# LPC8N04 register map
File version: 0.1
CPU: CM0PLUS r0p0, little endian, no MPU, no FPU, 2 interrupt priority bits
Registers are 32-bit, read-write, no defined reset value unless marked. A register's access mark holds for its fields unless they carry their own. Offsets are from the block's base; [hi:lo] are bit positions; {n}, {i} and the like mark numbered series; 'fields as' and 'values as' point back to an identical list.

## I2C0 — I2C Bus Controller 0
Base 0x40000000
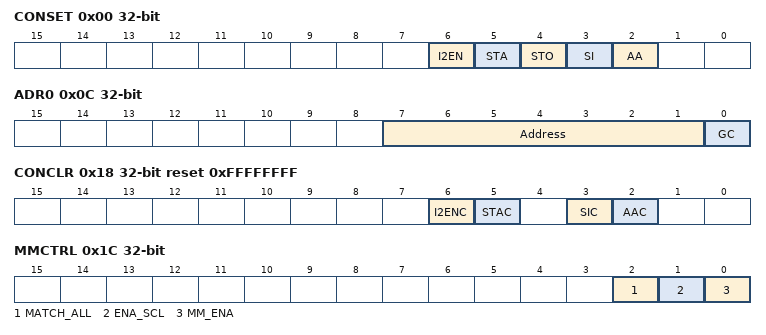
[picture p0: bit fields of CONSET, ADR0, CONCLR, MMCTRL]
0x00 CONSET — I2C Control Set Register. When a one is written to a bit of this register, the corresponding bit in the I2C control register is set. Writing a zero has no effect on the corresponding bit in the I2C control register.
  [6] I2EN — I2C interface enable
  [5] STA — START flag
  [4] STO — STOP flag
  [3] SI — I2C interrupt flag
  [2] AA — Assert acknowledge flag
0x04 STAT ro reset 0xF8 (reset mask 0x0) — I2C Status Register. During I2C operation, this register provides detailed status codes that allow software to determine the next action needed.
  [7:3] Status — Actual status information about the I2C interface
0x08 DAT — I2C Data Register. During master or slave transmit mode, data to be transmitted is written to this register. During master or slave receive mode, data that has been received may be read from this register.
  [7:0] Data — This register holds data values that have been received or are to be transmitted.
0x0C ADR0 — I2C Slave Address Register 0. Contains the 7-bit slave address for operation of the I2C interface in slave mode, and is not used in master mode. The least significant bit determines whether a slave responds to the General Call address. This address is also used for device wakeup.
  [7:1] Address — The I2C device address in slave ode
  [0] GC — General call enable bit
0x10 SCLH reset 0x4 (reset mask 0x0) — SCH Duty Cycle Register High Half Word. Determines the high time of the I2C clock.
  [15:0] SCLH — Count for SCL high time period selection.
0x14 SCLL reset 0x4 (reset mask 0x0) — SCL Duty Cycle Register Low Half Word. Determines the low time of the I2C clock. I2nSCLL and I2nSCLH together determine the clock frequency generated by an I2C master and certain times used in slave mode.
  [15:0] SCLL — Count for SCL low time period selection.
0x18 CONCLR wo reset 0xFFFFFFFF (reset mask 0x0) — I2C Control Clear Register. When a one is written to a bit of this register, the corresponding bit in the I2C control register is cleared. Writing a zero has no effect on the corresponding bit in the I2C control register
  [6] I2ENC — I2C interface disable bit
  [5] STAC — START flag clear bit
  [3] SIC — I2C Interrupt clear bit
  [2] AAC — Assert acknowledge clear bit
0x1C MMCTRL — Monitor mode control register
  [2] MATCH_ALL — Select interrupt register match
    0=MATCH (When this bit is cleared, an interrupt will only be generated when a match occurs to one of the (up-to) four address registers described above. That is, the module will respond as a normal slave as far as address-recognition is concerned.); 1=ANY_ADDRESS (When this bit is set to 1 and the I2C is in monitor mode, an interrupt will be generated on ANY address received. This will enable the part to monitor all traffic on the bus.)
  [1] ENA_SCL — SCL output enable
    0=HIGH (When this bit is cleared to 0, the SCL output will be forced high when the module is in monitor mode. As described above, this will prevent the module from having any control over the I2C clock line.); 1=LOW (When this bit is set, the I2C module may exercise the same control over the clock line that it would in normal operation. This means that, acting as a slave peripheral, the I2C module can stretch the clock line (hold it low) until it has had time to respond to an I2C interrupt)
  [0] MM_ENA — Monitor mode enable
    0=DISABLED (Monitor mode disabled); 1=ENABLED (The I2C module will enter monitor mode. In this mode the SDA output will be forced high. This will prevent the I2C module from outputting data of any kind (including ACK) onto the I2C data bus. Depending on the state of the ENA_SCL bit, the output may be also forced high, preventing the module from having control over the I2C clock line.)
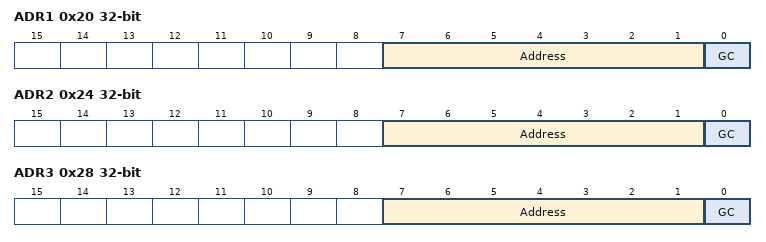
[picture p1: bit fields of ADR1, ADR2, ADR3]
0x20 ADR1 — I2C Slave Address Register 1. Contains the 7-bit slave address for operation of the I2C interface in slave mode, and is not used in master mode. The least significant bit determines whether a slave responds to the General Call address.
  [7:1] Address — The I2C device address for slave mode
  [0] GC — General call enable bit
0x24 ADR2 — I2C Slave Address Register 2. Contains the 7-bit slave address for operation of the I2C interface in slave mode, and is not used in master mode. The least significant bit determines whether a slave responds to the General Call address
  fields as ADR1
0x28 ADR3 — I2C Slave Address Register 3. Contains the 7-bit slave address for operation of the I2C interface in slave mode, and is not used in master mode. The least significant bit determines whether a slave responds to the General Call address
  fields as ADR1
0x2C DATA_BUFFER ro — Data buffer register. The contents of the 8 MSBs of the DAT shift register will be transferred to the DATA_BUFFER automatically after every nine bits (8 bits of data plus ACK or NACK) has been received on the bus.
  [7:0] Data — Contents of the 8 MSBs of the DAT shift register.
{0x30+4i} MASK{i} (i=0..3) — I2C Slave address mask register {i}. This mask register is associated with ADR{i} to determine an address match. The mask register has no effect when comparing to the General Call address (0x0000000).
  [7:1] Data — Mask bits
